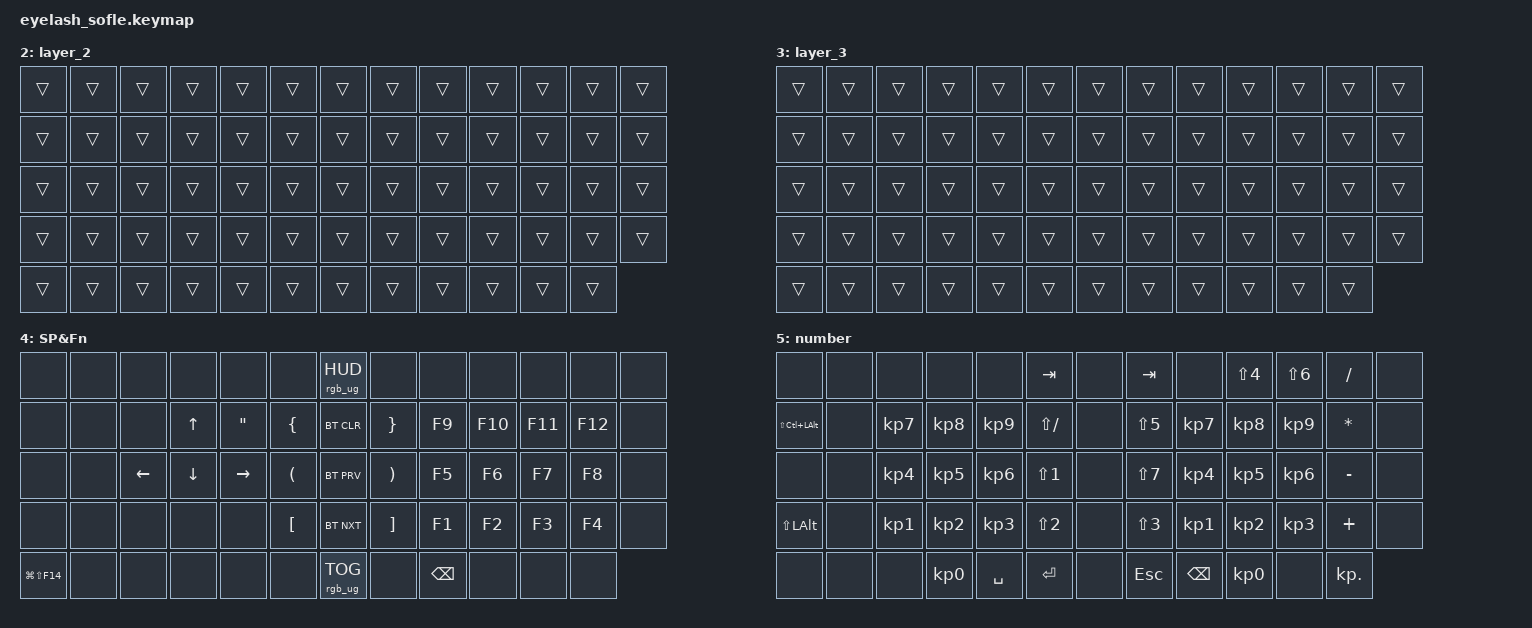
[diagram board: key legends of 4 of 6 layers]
#define ZMK_POINTING_DEFAULT_MOVE_VAL 1500  // default: 600
#define ZMK_POINTING_DEFAULT_SCRL_VAL 20    // default: 10

#include <dt-bindings/zmk/mouse.h>
#include <input/processors.dtsi>
#include <behaviors.dtsi>
#include <dt-bindings/zmk/bt.h>
#include <dt-bindings/zmk/keys.h>
#include <dt-bindings/zmk/pointing.h>
#include <dt-bindings/zmk/pointing.h>
#include <dt-bindings/zmk/rgb.h>

/*

   &mmv_input_listener {
       input-processors = <&zip_xy_scaler 2 1>;
   };

   &msc_input_listener {
       input-processors = <&zip_xy_scaler 2 1>;
   };

 */

#define ZMK_MOUSE_DEFAULT_MOVE_VAL 1200  // 600
#define ZMK_MOUSE_DEFAULT_SCRL_VAL 20    // 10

/ {
    behaviors {
        mmv {
            acceleration-exponent = <1>;      // 1
            time-to-max-speed-ms = <900>;    // 40
            delay-ms = <0>;                   // 0
        };

        msc {
            acceleration-exponent = <1>;      // 0
            time-to-max-speed-ms = <400>;      // 500
            delay-ms = <0>;                   //   10
        };
    };

    scroll_encoder: scroll_encoder {
        compatible = "zmk,behavior-sensor-rotate";
        #sensor-binding-cells = <0>;
        bindings = <&msc SCRL_DOWN>, <&msc SCRL_UP>;

        tap-ms = <30>;
    };

    SandS: SandS {
        compatible = "zmk,behavior-hold-tap";
        label = "SANDS";
        bindings = <&kp>, <&kp>;

        #binding-cells = <2>;
        tapping-term-ms = <200>;
        flavor = "hold-preferred";
        retro-tap;
    };

    keymap {
        compatible = "zmk,keymap";

        layer_0 {
		
// ------------------------------------------------------------------------------------------------------------
// |  ESC  |  1  |  2  |  3   |  4   |  5   |                   |  6   |  7    |  8    |  9   |   0   | BKSPC |
// |  TAB  |  Q  |  W  |  E   |  R   |  T   |                   |  Y   |  U    |  I    |  O   |   P   |   Å   |
// | SHIFT |  A  |  S  |  D   |  F   |  G   |                   |  H   |  J    |  K    |  L   |   Ö   |   Ä   |
// | LCTRL |  Z  |  X  |  C   |  V   |  B   |  MUTE  |  |       |  N   |  M    |  ,    |  .   |   /   | SHIFT |
//               | GUI | ALT  | CTRL | LOWER|  ENTER |  | SPACE | RAISE| CTRL  | ALT   | GUI  |

            bindings = <
&kp ESCAPE       &kp NUMBER_1  &kp NUMBER_2  &kp NUMBER_3    &kp NUMBER_4  &kp N5         &mmv MOVE_Y(-600)  &kp NUMBER_6  &kp N7        &kp N8             &kp N9        &kp N0         &kp BACKSPACE
&kp TAB          &kp Q         &kp W         &kp E           &kp R         &kp T          &mmv MOVE_Y(600)   &kp Y         &kp U         &kp I              &kp O         &kp P          &kp LBKT
&kp LEFT_SHIFT   &kp A         &kp S         &kp D           &kp F         &kp G          &mmv MOVE_X(-600)  &kp H         &kp J         &kp K              &kp L         &kp SEMICOLON  &kp SQT
&kp LCTRL        &kp Z         &kp X         &kp C           &kp V         &kp B          &mmv MOVE_X(600)   &kp N         &kp M         &kp COMMA          &kp PERIOD    &kp FSLH       &kp RIGHT_SHIFT
&kp C_MUTE       &kp LEFT_GUI  &kp LEFT_ALT  &kp GRAVE       &mo 1         &kp ENTER      &mkp LCLK    	     &lt 2 SPACE   &mo 2         &kp RIGHT_CONTROL  &kp RIGHT_ALT &kp RIGHT_GUI  &kp BACKSLASH
			>;

            sensor-bindings = <&inc_dec_kp C_VOLUME_UP C_VOL_DN>;
            display-name = "mac-base";
        };

        layer_1 {
// ------------------------------------------------------------------------------------------------------------
// |       |  F1 |  F2 |  F3  |  F4  |  F5  |                   |  F6  |  F7   |  F8   |  F9  |  F10  |  F11  |
// |   `   |  1  |  2  |  3   |  4   |  5   |                   |  6   |  7    |  8    |  9   |   0   |  F12  |
// |       |  !  |  @  |  #   |  $   |  %   |                   |  ^   |  &    |  *    |  (   |   )   |   |   |
// |       |  =  |  -  |  +   |  {   |  }   |        |  |       |  [   |  ]    |  ;    |  :   |   \   |       |
//               |     |      |      |      |        |  |       |      |       |       |      |

            display-name = "win-base";
            bindings = <
&trans                  &kp F1        &kp F2        &kp F3          &kp F4                 &kp F5           &mmv MOVE_Y(-600)     &kp F6             &kp F7             &kp F8                &kp F9                 &kp F10               &kp F11
&kp GRAVE               &kp 1         &kp 2         &kp 3           &kp 4                  &kp 5            &mmv MOVE_Y(600)      &kp 6              &kp 7              &kp 8                 &kp 9                  &kp 0                 &kp F12
&trans                  &kp EXCL      &kp AT        &kp HASH        &kp DLLR               &kp PRCNT        &mmv MOVE_X(-600)     &kp CARET          &kp ASTRK          &kp LEFT_PARENTHESIS  &kp RIGHT_PARENTHESIS  &kp PIPE              &trans
&trans 	 				&kp EQUAL     &kp MINUS     &kp PLUS        &kp LEFT_BRACE         &kp RIGHT_BRACE  &mmv MOVE_X(600)      &kp LEFT_BRACKET   &kp RIGHT_BRACKET  &kp SQT               &kp EQUAL              &kp NON_US_BACKSLASH  &trans
&trans                  &trans        &trans        &trans          &trans                 &trans           &mkp LCLK             &trans             &trans             &trans                &trans                 &trans                &trans
            >;

            sensor-bindings = <&inc_dec_kp C_VOLUME_UP C_VOL_DN>;
        };

        layer_2 {
// ------------------------------------------------------------------------------------------------------------
// | BTCLR | BT1  | BT2  |  BT3  |  BT4  |  BT5 |                |      |      |       |      |       |       |
// |       | INS  | PSCR | GUI   |       |      |                | PGUP |      |   ^   |      |       |       |
// |       | ALT  | CTRL | SHIFT |       | CAPS |                | PGDN |   <- |   v   |  ->  |  DEL  | BKSPC |
// |       | UNDO | CUT  | COPY  | PASTE |      |      |  |      |      |      |       |      |       |       |
//                |      |       |       |      |      |  |      |      |      |       |      |

            bindings = <
&trans  &trans  &trans  &trans  &trans  &trans    &trans  &trans  &trans  &trans  &trans  &trans  &trans
&trans  &trans  &trans  &trans  &trans  &trans    &trans  &trans  &trans  &trans  &trans  &trans  &trans
&trans  &trans  &trans  &trans  &trans  &trans    &trans  &trans  &trans  &trans  &trans  &trans  &trans
&trans  &trans  &trans  &trans  &trans  &trans    &trans  &trans  &trans  &trans  &trans  &trans  &trans
&trans  &trans  &trans  &trans  &trans  &trans    &trans  &trans  &trans  &trans  &trans  &trans
            >;
        };

        layer_3 {
            bindings = <
&trans  &trans  &trans  &trans  &trans  &trans    &trans  &trans  &trans  &trans  &trans  &trans  &trans
&trans  &trans  &trans  &trans  &trans  &trans    &trans  &trans  &trans  &trans  &trans  &trans  &trans
&trans  &trans  &trans  &trans  &trans  &trans    &trans  &trans  &trans  &trans  &trans  &trans  &trans
&trans  &trans  &trans  &trans  &trans  &trans    &trans  &trans  &trans  &trans  &trans  &trans  &trans
&trans  &trans  &trans  &trans  &trans  &trans    &trans  &trans  &trans  &trans  &trans  &trans
            >;
        };

        layer_4 {
            bindings = <
&none            &none  &none     &none         &none              &none                   &rgb_ug RGB_HUD  &none                  &none          &none    &none    &none    &none
&none            &none  &none     &kp UP_ARROW  &kp DOUBLE_QUOTES  &kp LEFT_BRACE          &bt BT_CLR       &kp RIGHT_BRACE        &kp F9         &kp F10  &kp F11  &kp F12  &none
&none            &none  &kp LEFT  &kp DOWN      &kp RIGHT          &kp LEFT_PARENTHESIS    &bt BT_PRV       &kp RIGHT_PARENTHESIS  &kp F5         &kp F6   &kp F7   &kp F8   &none
&none            &none  &none     &none         &none              &kp LEFT_BRACKET        &bt BT_NXT       &kp RIGHT_BRACKET      &kp F1         &kp F2   &kp F3   &kp F4   &none
&kp LG(LS(F14))  &none  &none     &none         &none              &none                   &rgb_ug RGB_TOG  &none                  &kp BACKSPACE  &none    &none    &none
            >;

            sensor-bindings = <&inc_dec_kp LA(LG(F13)) RG(F13)>;
            label = "SP&Fn";
        };

        layer_5 {
            bindings = <
&none                 &none  &none            &none            &none            &kp TAB             &none  &kp TAB           &none            &kp LS(NUMBER_4)  &kp LS(NUMBER_6)  &kp SLASH     &none
&kp LS(LC(LEFT_ALT))  &none  &kp KP_NUMBER_7  &kp KP_NUMBER_8  &kp KP_NUMBER_9  &kp LS(SLASH)       &none  &kp LS(N5)        &kp KP_NUMBER_7  &kp KP_NUMBER_8   &kp KP_NUMBER_9   &kp ASTERISK  &none
&none                 &none  &kp KP_NUMBER_4  &kp KP_NUMBER_5  &kp KP_NUMBER_6  &kp LS(NUMBER_1)    &none  &kp LS(N7)        &kp KP_NUMBER_4  &kp KP_NUMBER_5   &kp KP_NUMBER_6   &kp MINUS     &none
&kp LS(LEFT_ALT)      &none  &kp KP_NUMBER_1  &kp KP_NUMBER_2  &kp KP_NUMBER_3  &kp LS(NUMBER_2)    &none  &kp LS(NUMBER_3)  &kp KP_NUMBER_1  &kp KP_NUMBER_2   &kp KP_NUMBER_3   &kp PLUS      &none
&none                 &none  &none            &kp KP_NUMBER_0  &kp SPACE        &kp RETURN          &none  &kp ESCAPE        &kp BACKSPACE    &kp KP_NUMBER_0   &none             &kp KP_DOT
            >;

            label = "number";
            sensor-bindings = <&scroll_encoder>;
        } ;
    };
};
